# nrf5340_application register map
Vendor: Nordic Semiconductor; Series: nrf53; File version: 1
CPU: CM33 r0p4, little endian, MPU, FPU, 3 interrupt priority bits, 69 interrupts
Registers are 32-bit, read-write, reset 0x0 unless marked. A register's access mark holds for its fields unless they carry their own. Offsets are from the block's base; [hi:lo] are bit positions; {n}, {i} and the like mark numbered series.

## CTI_S — Cross-Trigger Interface control. NOTE: this is not a separate peripheral, but describes CM33 functionality.
Base 0xE0042000
0x00 CTICONTROL
  [0] GLBEN — Enables or disables the CTI.
    0=Disabled (All cross-triggering mapping logic functionality is disabled.); 1=Enabled (Cross-triggering mapping logic functionality is enabled.)
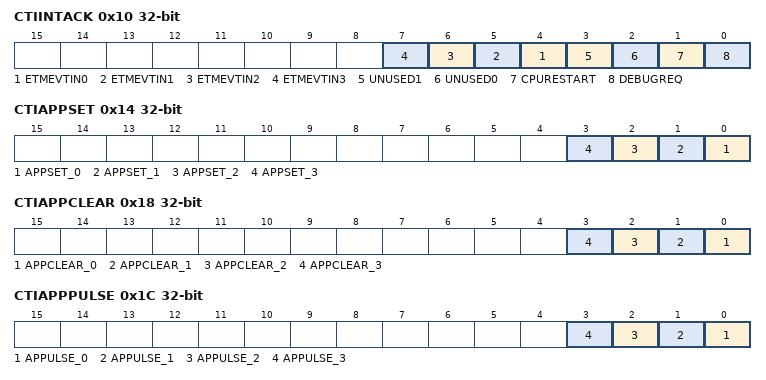
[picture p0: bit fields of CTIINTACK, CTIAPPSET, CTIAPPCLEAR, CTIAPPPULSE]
0x10 CTIINTACK wo — CTI Interrupt Acknowledge register
  [all] fields
    on write: 1=Acknowledge (Clears the ctitrigout.)
  [n+4] ETMEVTIN{n} (n=0..3) — ETM Event Input {n}
  [3] UNUSED1
  [2] UNUSED0
  [1] CPURESTART — Processor Restart
  [0] DEBUGREQ — Processor debug request
0x14 CTIAPPSET — CTI Application Trigger Set register
  [n] APPSET_{n} (n=0..3) — Application trigger event for channel {n}.
    on read: 0=Inactive (Application trigger {n} is inactive.); 1=Active (Application trigger {n} is active.) | on write: 1=Activate (Generate channel event for channel {n}.)
0x18 CTIAPPCLEAR wo — CTI Application Trigger Clear register
  [n] APPCLEAR_{n} (n=0..3) — Sets the corresponding bits in the CTIAPPSET to 0. There is one bit of the register for each channel.
    on write: 1=Clears the event for channel {n}
0x1C CTIAPPPULSE wo — CTI Application Pulse register
  [n] APPULSE_{n} (n=0..3) — Setting a bit HIGH generates a channel event pulse for the selected channel. There is one bit of the register for each channel.
    on write: 1=Generates an event pulse on channel {n}
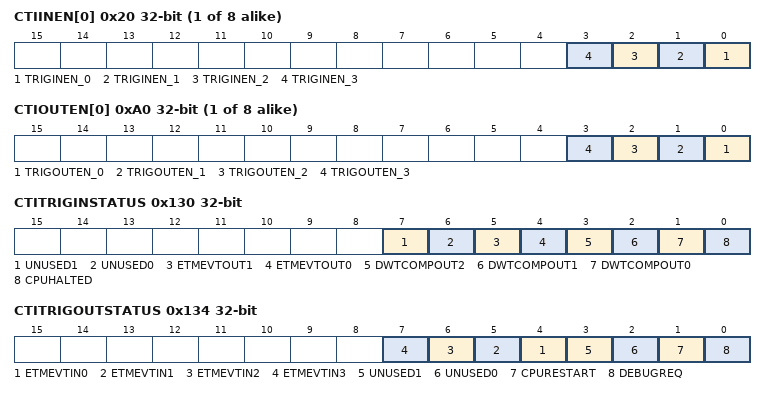
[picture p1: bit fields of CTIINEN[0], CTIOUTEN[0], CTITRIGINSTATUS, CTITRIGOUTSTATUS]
{0x20+4i} CTIINEN[{i}] (i=0..7) — Description collection: CTI Trigger input
  [n] TRIGINEN_{n} (n=0..3) — Enables a cross trigger event to channel {n} when a ctitrigin input is activated.
    0=Disabled (Input trigger n events are ignored by channel {n}.); 1=Enabled (When an event is received on input trigger n (ctitrigin[n]), generate an event on channel {n}.)
{0xA0+4i} CTIOUTEN[{i}] (i=0..7) — Description collection: CTI Trigger output
  [n] TRIGOUTEN_{n} (n=0..3) — Enables a cross trigger event to ctitrigout when channel {n} is activated.
    0=Disabled (Channel {n} is ignored by output trigger n.); 1=Enabled (When an event occurs on channel {n}, generate an event on output event n (ctitrigout[n]).)
0x130 CTITRIGINSTATUS ro — CTI Trigger In Status register
  [7] UNUSED1
    1=Active (Ctitrigin 7 is active.); 0=Inactive (Ctitrigin 7 is inactive.)
  [6] UNUSED0
    1=Active (Ctitrigin 6 is active.); 0=Inactive (Ctitrigin 6 is inactive.)
  [5] ETMEVTOUT1 — ETM Event Output 1
    1=Active (Ctitrigin 5 is active.); 0=Inactive (Ctitrigin 5 is inactive.)
  [4] ETMEVTOUT0 — ETM Event Output 0
    1=Active (Ctitrigin 4 is active.); 0=Inactive (Ctitrigin 4 is inactive.)
  [3] DWTCOMPOUT2 — DWT Comparator Output 2
    1=Active (Ctitrigin 3 is active.); 0=Inactive (Ctitrigin 3 is inactive.)
  [2] DWTCOMPOUT1 — DWT Comparator Output 1
    1=Active (Ctitrigin 2 is active.); 0=Inactive (Ctitrigin 2 is inactive.)
  [1] DWTCOMPOUT0 — DWT Comparator Output 0
    1=Active (Ctitrigin 1 is active.); 0=Inactive (Ctitrigin 1 is inactive.)
  [0] CPUHALTED — Processor Halted
    1=Active (Ctitrigin 0 is active.); 0=Inactive (Ctitrigin 0 is inactive.)
0x134 CTITRIGOUTSTATUS ro — CTI Trigger Out Status register
  [n+4] ETMEVTIN{n} (n=0..3) — ETM Event Input {n}
    1=Active (Ctitrigout {n+4} is active.); 0=Inactive (Ctitrigout {n+4} is inactive.)
  [3] UNUSED1
    1=Active (Ctitrigout 3 is active.); 0=Inactive (Ctitrigout 3 is inactive.)
  [2] UNUSED0
    1=Active (Ctitrigout 2 is active.); 0=Inactive (Ctitrigout 2 is inactive.)
  [1] CPURESTART — Processor Restart
    1=Active (Ctitrigout 1 is active.); 0=Inactive (Ctitrigout 1 is inactive.)
  [0] DEBUGREQ — Processor debug request
    1=Active (Ctitrigout 0 is active.); 0=Inactive (Ctitrigout 0 is inactive.)
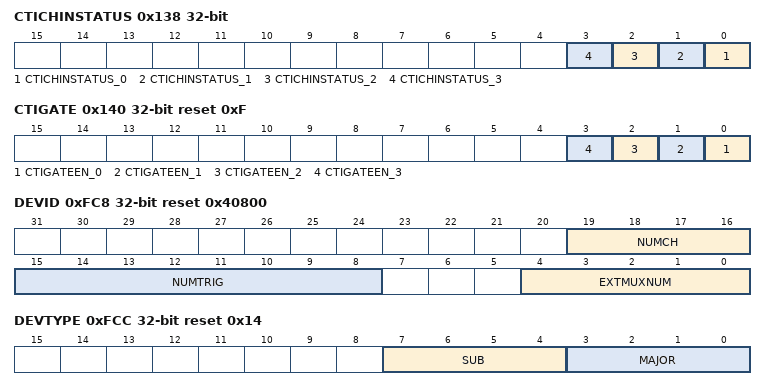
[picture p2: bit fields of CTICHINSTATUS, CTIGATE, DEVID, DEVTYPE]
0x138 CTICHINSTATUS ro — CTI Channel In Status register
  [n] CTICHINSTATUS_{n} (n=0..3) — Shows the status of the ctitrigin {n} input.
    1=Active (Ctichin {n} is active.); 0=Inactive (Ctichin {n} is inactive.)
0x140 CTIGATE reset 0xF — Enable CTI Channel Gate register
  [n] CTIGATEEN_{n} (n=0..3) — Enable ctichout{n}.
    1=Enabled (Enable ctichout channel {n} propagation.); 0=Disabled (Disable ctichout channel {n} propagation.)
0xFBC DEVARCH ro reset 0x47701A14 — Device Architecture register
  [0] Architecture — Contains the CTI device architecture.
0xFC8 DEVID ro reset 0x40800 — Device Configuration register
  [19:16] NUMCH — Number of ECT channels available.
  [15:8] NUMTRIG — Number of ECT triggers available.
  [4:0] EXTMUXNUM — Indicates the number of multiplexers available on Trigger Inputs and Trigger Outputs that are using asicctl. The default value of 0b00000 indicates that no multiplexing is present.
0xFCC DEVTYPE ro reset 0x14 — Device Type Identifier register
  [7:4] SUB — Sub-classification of the type of the debug component as specified in the Arm Architecture Specification within the major classification as specified in the MAJOR field.
    1=Crosstrigger (Indicates that this component is a sub-triggering component.)
  [3:0] MAJOR — Major classification of the type of the debug component as specified in the Arm Architecture Specification for this debug and trace component.
    4=Controller (Indicates that this component allows a debugger to control other components in an Arm CoreSight SoC-400 system.)
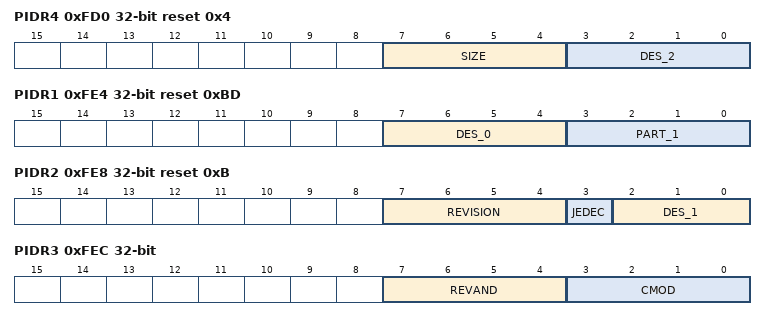
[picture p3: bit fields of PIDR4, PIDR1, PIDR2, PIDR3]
0xFD0 PIDR4 ro reset 0x4 — Peripheral ID4 Register
  [7:4] SIZE — Always 0b0000. Indicates that the device only occupies 4KB of memory.
  [3:0] DES_2 — Together, PIDR1.DES_0, PIDR2.DES_1, and PIDR4.DES_2 identify the designer of the component.
    4=Code (JEDEC continuation code.)
{0xFC0+4i} PIDR{i} ro (i=5..7) — Peripheral ID{i} register
0xFE0 PIDR0 ro reset 0x21 — Peripheral ID0 Register
  [7:0] PART_0 — Bits[7:0] of the 12-bit part number of the component. The designer of the component assigns this part number.
    33=PartnumberL (Indicates bits[7:0] of the part number of the component.)
0xFE4 PIDR1 ro reset 0xBD — Peripheral ID1 Register
  [7:4] DES_0 — Together, PIDR1.DES_0, PIDR2.DES_1, and PIDR4.DES_2 identify the designer of the component.
    11=Arm (Arm. Bits[3:0] of the JEDEC JEP106 Identity Code)
  [3:0] PART_1 — Bits[11:8] of the 12-bit part number of the component. The designer of the component assigns this part number.
    13=PartnumberH (Indicates bits[11:8] of the part number of the component.)
0xFE8 PIDR2 ro reset 0xB — Peripheral ID2 Register
  [7:4] REVISION — Peripheral revision
    0=Rev0p0 (This device is at r0p0)
  [3] JEDEC — Always 1. Indicates that the JEDEC-assigned designer ID is used.
  [2:0] DES_1 — Together, PIDR1.DES_0, PIDR2.DES_1, and PIDR4.DES_2 identify the designer of the component.
    3=Arm (Arm. Bits[6:4] of the JEDEC JEP106 Identity Code)
0xFEC PIDR3 ro — Peripheral ID3 Register
  [7:4] REVAND — Indicates minor errata fixes specific to the revision of the component being used, for example metal fixes after implementation. In most cases, this field is 0b0000. Arm recommends that the component designers ensure that a metal fix can change this field if required, for example, by driving it from registers that reset to 0b0000.
    0=NoErrata (Indicates that there are no errata fixes to this component.)
  [3:0] CMOD — Customer Modified. Indicates whether the customer has modified the behavior of the component. In most cases, this field is 0b0000. Customers change this value when they make authorized modifications to this component.
    0=Unmodified (Indicates that the customer has not modified this component.)
0xFF0 CIDR0 ro reset 0xD — Component ID0 Register
  [7:0] PRMBL_0 — Preamble[0]. Contains bits[7:0] of the component identification code.
    13=Value (Bits[7:0] of the identification code.)
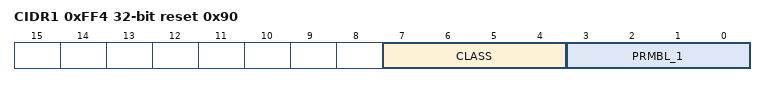
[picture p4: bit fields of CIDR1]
0xFF4 CIDR1 ro reset 0x90 — Component ID1 Register
  [7:4] CLASS — Class of the component, for example, whether the component is a ROM table or a generic CoreSight component. Contains bits[15:12] of the component identification code
    9=Coresight (Indicates that the component is a CoreSight component.)
  [3:0] PRMBL_1 — Preamble[1]. Contains bits[11:8] of the component identification code.
    0=Value (Bits[11:8] of the identification code.)
0xFF8 CIDR2 ro reset 0x5 — Component ID2 Register
  [7:0] PRMBL_2 — Preamble[2]. Contains bits[23:16] of the component identification code.
    5=Value (Bits[23:16] of the identification code.)
0xFFC CIDR3 ro reset 0xB1 — Component ID3 Register
  [7:0] PRMBL_3 — Preamble[3]. Contains bits[31:24] of the component identification code.
    177=Value (Bits[31:24] of the identification code.)

## Notices in the file
Copyright (c) 2010 - 2021, Nordic Semiconductor ASA All rights reserved.
Redistribution and use in source and binary forms, with or without
modification, are permitted provided that the following conditions are met:
1. Redistributions of source code must retain the above copyright notice, this
list of conditions and the following disclaimer.
2. Redistributions in binary form must reproduce the above copyright
notice, this list of conditions and the following disclaimer in the
documentation and/or other materials provided with the distribution.
3. Neither the name of Nordic Semiconductor ASA nor the names of its
contributors may be used to endorse or promote products derived from this
software without specific prior written permission.
THIS SOFTWARE IS PROVIDED BY THE COPYRIGHT HOLDERS AND CONTRIBUTORS "AS IS"
AND ANY EXPRESS OR IMPLIED WARRANTIES, INCLUDING, BUT NOT LIMITED TO, THE
IMPLIED WARRANTIES OF MERCHANTABILITY, AND FITNESS FOR A PARTICULAR PURPOSE
ARE DISCLAIMED. IN NO EVENT SHALL NORDIC SEMICONDUCTOR ASA OR CONTRIBUTORS BE
LIABLE FOR ANY DIRECT, INDIRECT, INCIDENTAL, SPECIAL, EXEMPLARY, OR
CONSEQUENTIAL DAMAGES (INCLUDING, BUT NOT LIMITED TO, PROCUREMENT OF
SUBSTITUTE GOODS OR SERVICES; LOSS OF USE, DATA, OR PROFITS; OR BUSINESS
INTERRUPTION) HOWEVER CAUSED AND ON ANY THEORY OF LIABILITY, WHETHER IN
CONTRACT, STRICT LIABILITY, OR TORT (INCLUDING NEGLIGENCE OR OTHERWISE)
ARISING IN ANY WAY OUT OF THE USE OF THIS SOFTWARE, EVEN IF ADVISED OF THE
POSSIBILITY OF SUCH DAMAGE.
